# STM32F0xx register map
File version: 1.0
Registers are 32-bit, read-write, reset 0x0 unless marked. A register's access mark holds for its fields unless they carry their own. Offsets are from the block's base; [hi:lo] are bit positions; lines under a group give offsets from that group; {n}, {i} and the like mark numbered series.

## TIM16 — General-purpose-timers
Base 0x40014400
Same registers: TIM17 0x40014800
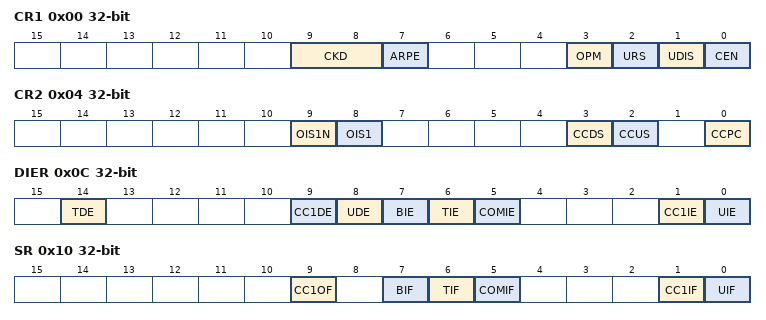
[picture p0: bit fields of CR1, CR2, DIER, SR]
0x00 CR1 — control register 1
  [9:8] CKD — Clock division
  [7] ARPE — Auto-reload preload enable
  [3] OPM — One-pulse mode
  [2] URS — Update request source
  [1] UDIS — Update disable
  [0] CEN — Counter enable
    0=disabled (Disable the Rising trigger.); 1=enabled (Enable the Rising trigger.)
0x04 CR2 — control register 2
  [9] OIS1N — Output Idle state 1
  [8] OIS1 — Output Idle state 1
  [3] CCDS — Capture/compare DMA selection
  [2] CCUS — Capture/compare control update selection
  [0] CCPC — Capture/compare preloaded control
0x0C DIER — DMA/Interrupt enable register
  [14] TDE — Trigger DMA request enable
  [9] CC1DE — Capture/Compare 1 DMA request enable
  [8] UDE — Update DMA request enable
  [7] BIE — Break interrupt enable
  [6] TIE — Trigger interrupt enable
  [5] COMIE — COM interrupt enable
  [1] CC1IE — Capture/Compare 1 interrupt enable
  [0] UIE — Update interrupt enable
0x10 SR — status register
  [9] CC1OF — Capture/Compare 1 overcapture flag
  [7] BIF — Break interrupt flag
  [6] TIF — Trigger interrupt flag
  [5] COMIF — COM interrupt flag
  [1] CC1IF — Capture/compare 1 interrupt flag
  [0] UIF — Update interrupt flag
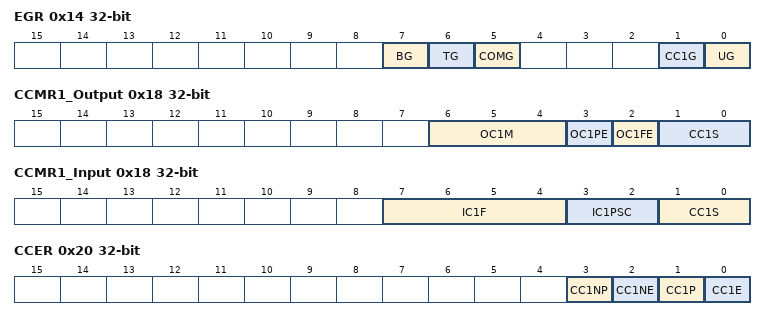
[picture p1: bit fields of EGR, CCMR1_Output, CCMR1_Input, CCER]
0x14 EGR wo — event generation register
  [7] BG — Break generation
  [6] TG — Trigger generation
  [5] COMG — Capture/Compare control update generation
  [1] CC1G — Capture/compare 1 generation
  [0] UG — Update generation
0x18 CCMR1_Output — capture/compare mode register (output mode)
  [6:4] OC1M — Output Compare 1 mode
  [3] OC1PE — Output Compare 1 preload enable
  [2] OC1FE — Output Compare 1 fast enable
  [1:0] CC1S — Capture/Compare 1 selection
0x18 CCMR1_Input (alternate view of CCMR1_Output) — capture/compare mode register 1 (input mode)
  [7:4] IC1F — Input capture 1 filter
  [3:2] IC1PSC — Input capture 1 prescaler
  [1:0] CC1S — Capture/Compare 1 selection
0x20 CCER — capture/compare enable register
  [3] CC1NP — Capture/Compare 1 output Polarity
  [2] CC1NE — Capture/Compare 1 complementary output enable
  [1] CC1P — Capture/Compare 1 output Polarity
  [0] CC1E — Capture/Compare 1 output enable
0x24 CNT — counter
  [15:0] CNT — counter value
0x28 PSC — prescaler
  [15:0] PSC — Prescaler value
0x2C ARR — auto-reload register
  [15:0] ARR — Auto-reload value
0x30 RCR — repetition counter register
  [7:0] REP — Repetition counter value
0x34 CCR1 — capture/compare register 1
  [15:0] CCR1 — Capture/Compare 1 value
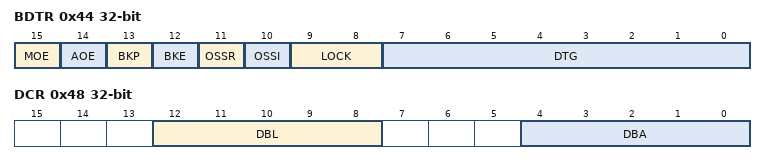
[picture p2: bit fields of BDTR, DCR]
0x44 BDTR — break and dead-time register
  [15] MOE — Main output enable
  [14] AOE — Automatic output enable
  [13] BKP — Break polarity
  [12] BKE — Break enable
  [11] OSSR — Off-state selection for Run mode
  [10] OSSI — Off-state selection for Idle mode
  [9:8] LOCK — Lock configuration
  [7:0] DTG — Dead-time generator setup
0x48 DCR — DMA control register
  [12:8] DBL — DMA burst length
  [4:0] DBA — DMA base address
0x4C DMAR — DMA address for full transfer
  [15:0] DMAB — DMA register for burst accesses

## TSC — Touch sensing controller
Base 0x40024000
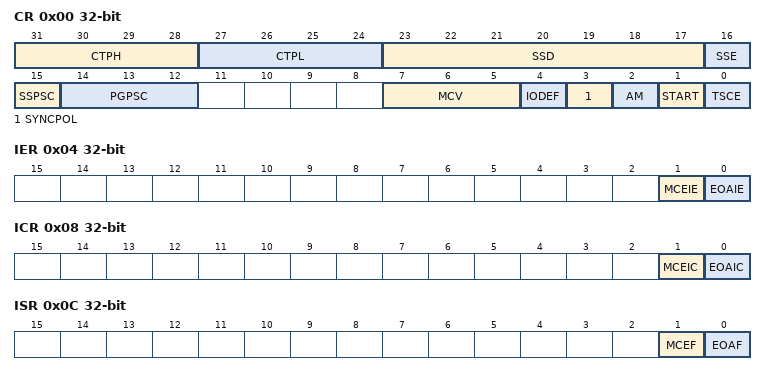
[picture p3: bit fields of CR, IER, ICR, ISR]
0x00 CR — control register
  [31:28] CTPH — Charge transfer pulse high
  [27:24] CTPL — Charge transfer pulse low
  [23:17] SSD — Spread spectrum deviation
  [16] SSE — Spread spectrum enable
  [15] SSPSC — Spread spectrum prescaler
  [14:12] PGPSC — pulse generator prescaler
  [7:5] MCV — Max count value
  [4] IODEF — I/O Default mode
  [3] SYNCPOL — Synchronization pin polarity
  [2] AM — Acquisition mode
  [1] START — Start a new acquisition
  [0] TSCE — Touch sensing controller enable
0x04 IER — interrupt enable register
  [1] MCEIE — Max count error interrupt enable
  [0] EOAIE — End of acquisition interrupt enable
0x08 ICR — interrupt clear register
  [1] MCEIC — Max count error interrupt clear
  [0] EOAIC — End of acquisition interrupt clear
0x0C ISR — interrupt status register
  [1] MCEF — Max count error flag
  [0] EOAF — End of acquisition flag
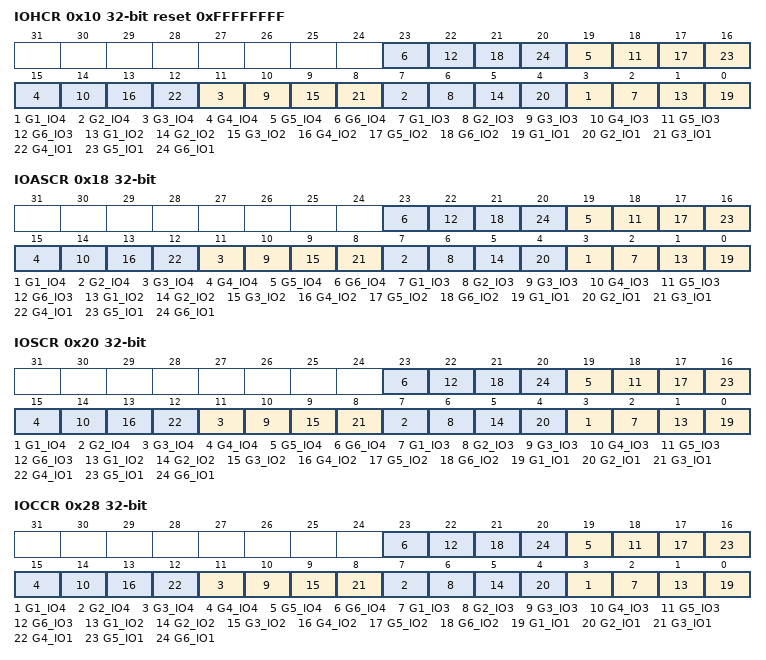
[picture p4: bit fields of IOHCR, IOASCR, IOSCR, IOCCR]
0x10 IOHCR reset 0xFFFFFFFF — I/O hysteresis control register
  [4n-1] G{n}_IO4 (n=1..6) — G{n}_IO4 Schmitt trigger hysteresis mode
  [4n-2] G{n}_IO3 (n=1..6) — G{n}_IO3 Schmitt trigger hysteresis mode
  [4n-3] G{n}_IO2 (n=1..6) — G{n}_IO2 Schmitt trigger hysteresis mode
  [4n-4] G{n}_IO1 (n=1..6) — G{n}_IO1 Schmitt trigger hysteresis mode
0x18 IOASCR — I/O analog switch control register
  [4n-1] G{n}_IO4 (n=1..6) — G{n}_IO4 analog switch enable
  [4n-2] G{n}_IO3 (n=1..6) — G{n}_IO3 analog switch enable
  [4n-3] G{n}_IO2 (n=1..6) — G{n}_IO2 analog switch enable
  [4n-4] G{n}_IO1 (n=1..6) — G{n}_IO1 analog switch enable
0x20 IOSCR — I/O sampling control register
  [4n-1] G{n}_IO4 (n=1..6) — G{n}_IO4 sampling mode
  [4n-2] G{n}_IO3 (n=1..6) — G{n}_IO3 sampling mode
  [4n-3] G{n}_IO2 (n=1..6) — G{n}_IO2 sampling mode
  [4n-4] G{n}_IO1 (n=1..6) — G{n}_IO1 sampling mode
0x28 IOCCR — I/O channel control register
  [4n-1] G{n}_IO4 (n=1..6) — G{n}_IO4 channel mode
  [4n-2] G{n}_IO3 (n=1..6) — G{n}_IO3 channel mode
  [4n-3] G{n}_IO2 (n=1..6) — G{n}_IO2 channel mode
  [4n-4] G{n}_IO1 (n=1..6) — G{n}_IO1 channel mode
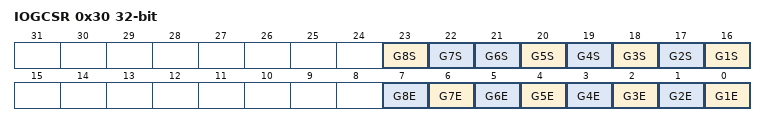
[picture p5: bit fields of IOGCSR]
0x30 IOGCSR access per field — I/O group control status register
  [23] G8S rw — Analog I/O group x status
  [22] G7S rw — Analog I/O group x status
  [n+15] G{n}S ro (n=1..6) — Analog I/O group x status
  [n-1] G{n}E rw (n=1..8) — Analog I/O group x enable
{0x30+4i} IOG{i}CR ro (i=1..6) — I/O group x counter register
  [13:0] CNT — Counter value
